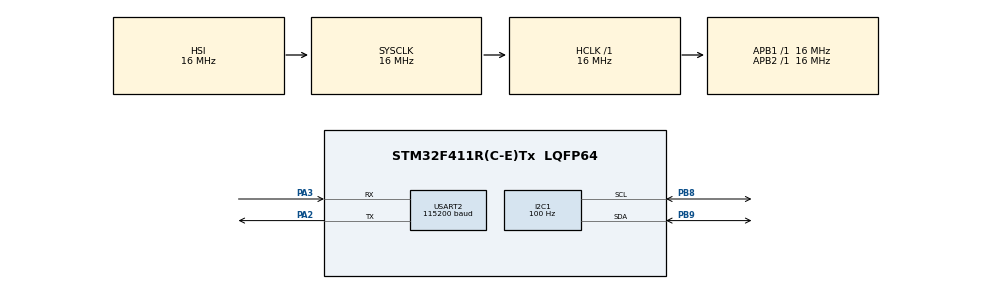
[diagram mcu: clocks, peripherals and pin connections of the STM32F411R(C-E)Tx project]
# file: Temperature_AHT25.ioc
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I2C1.ClockSpeed=100
Mcu.Family=STM32F4
Mcu.Name=STM32F411R(C-E)Tx
Mcu.Package=LQFP64
NVIC.PriorityGroup=NVIC_PRIORITYGROUP_4
PA2.Mode=Asynchronous
PA2.Signal=USART2_TX
PA3.Mode=Asynchronous
PA3.Signal=USART2_RX
PB8.Mode=I2C
PB8.Signal=I2C1_SCL
PB9.Mode=I2C
PB9.Signal=I2C1_SDA
ProjectManager.HeapSize=0x200
ProjectManager.StackSize=0x400
ProjectManager.TargetToolchain=STM32CubeIDE
RCC.AHBFreq_Value=16000000
RCC.APB1Freq_Value=16000000
RCC.APB2Freq_Value=16000000
RCC.CortexFreq_Value=16000000
RCC.HSE_VALUE=25000000
RCC.HSI_VALUE=16000000
RCC.LSE_VALUE=32768
RCC.SYSCLKFreq_VALUE=16000000
RCC.VCOOutputFreq_Value=192000000
USART2.BaudRate=115200
USART2.VirtualMode=VM_ASYNC
board=custom

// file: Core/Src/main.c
/* USER CODE BEGIN Header */
/**
  ******************************************************************************
  * @file           : main.c
  * @brief          : Main program body
  ******************************************************************************
  * @attention
  *
  * Copyright (c) 2023 STMicroelectronics.
  * All rights reserved.
  *
  * This software is licensed under terms that can be found in the LICENSE file
  * in the root directory of this software component.
  * If no LICENSE file comes with this software, it is provided AS-IS.
  *
  ******************************************************************************
  */
/* USER CODE END Header */
#include "main.h"
#include "stdio.h"
#include "string.h"

/* USER CODE BEGIN Includes */
#define AHT25_ADDR 0x38
#define AHT25_MEASURE_CMD 0xAC
#define REG_TEMP 0x00

/* USER CODE END Includes */

I2C_HandleTypeDef hi2c1;

UART_HandleTypeDef huart2;

/* USER CODE BEGIN PV */

//static const uint8_t AHT25_ADDR = 0x38 << 1;
//static const uint8_t REG_TEMP = 0xE1;
/* USER CODE END PV */

void SystemClock_Config(void);
static void MX_GPIO_Init(void);
static void MX_I2C1_Init(void);
static void MX_USART2_UART_Init(void);

int main(void)
{
  /* USER CODE BEGIN 1 */

//	HAL_StatusTypeDef ret;
//	uint8_t buf[12];
//	int16_t val;
//	float temp_c;

  /* USER CODE END 1 */
	  uint8_t buf[12];
	  int16_t temperature;
	  float temp_c;

  /* MCU Configuration--------------------------------------------------------*/

  /* Reset of all peripherals, Initializes the Flash interface and the Systick. */
  HAL_Init();

  /* Configure the system clock */
  SystemClock_Config();

  /* Initialize all configured peripherals */
  MX_GPIO_Init();
  MX_I2C1_Init();
  MX_USART2_UART_Init();

  /* Infinite loop */
  /* USER CODE BEGIN WHILE */
//  while (1)
//  {
//
//    // Tell TMP102 that we want to read from the temperature register
//    buf[0] = REG_TEMP;
//    ret = HAL_I2C_Master_Transmit(&hi2c1, AHT25_ADDR, buf, 1, HAL_MAX_DELAY);
//    HAL_Delay(500);
//    if ( ret != HAL_OK ) {
//      strcpy((char*)buf, "Error Tx\r\n");
//    } else {
//
//      // Read 2 bytes from the temperature register
//      ret = HAL_I2C_Master_Receive(&hi2c1, AHT25_ADDR, buf, 2, HAL_MAX_DELAY);
//      if ( ret != HAL_OK ) {
//        strcpy((char*)buf, "Error Rx\r\n");
//      } else {
//
//        //Combine the bytes
//        val = ((int16_t)buf[0] << 4) | (buf[1] >> 4);
//
//        // Convert to 2's complement, since temperature can be negative
//        if ( val > 0x7FF ) {
//          val |= 0xF000;
//        }
//
//        // Convert to float temperature value (Celsius)
//        temp_c = val * 0.0625;
//
//        // Convert temperature to decimal format
//        temp_c *= 100;
//        sprintf((char*)buf,
//              "%u.%u C\r\n",
//              ((unsigned int)temp_c / 100),
//              ((unsigned int)temp_c % 100));
//      }
//    }
//
//    // Send out buffer (temperature or error message)
//    HAL_UART_Transmit(&huart2, buf, strlen((char*)buf), HAL_MAX_DELAY);
//
//    // Wait
//    HAL_Delay(500);
//
//    /* USER CODE END WHILE */
//
//    /* USER CODE BEGIN 3 */
//  }
  /* USER CODE END 3 */
//  while (1)
//    {
//      buf[0] = ;
//      if (HAL_I2C_Master_Transmit(&hi2c1, AHT25_ADDR, buf, 1, 100) != HAL_OK)
//      {
//        strcpy((char*)buf, "Error Tx\r\n");
//
//        //strcpy((char*)buf, "Error Rx\r\n");
//      }
//      else
//      {
//        HAL_Delay(80);  // Wait for measurement completion (adjust delay if needed)
//
//        if (HAL_I2C_Master_Receive(&hi2c1, AHT25_ADDR, buf, 6, HAL_MAX_DELAY) != HAL_OK)
//        {
//          strcpy((char*)buf, "Error Rx\r\n");
//        }
//        else
//        {
//          temperature = ((int16_t)buf[2] << 8) | buf[3];
//
//          if (temperature > 0x7FF)
//          {
//            temperature = temperature | 0xF000;
//          }
//
//          temp_c = temperature * 0.1;
//
//          char temp_str[20];
//          sprintf(temp_str, "%.2f C\r\n", temp_c);
//          HAL_UART_Transmit(&huart2, (uint8_t*)temp_str, strlen(temp_str), HAL_MAX_DELAY);
//        }
//      }
//      HAL_UART_Transmit(&huart2, buf, strlen((char*)buf), HAL_MAX_DELAY);
//      HAL_Delay(500);
//    }

  while (1)
  {
    buf[0] = AHT25_MEASURE_CMD;

    if (HAL_I2C_Master_Transmit(&hi2c1, AHT25_ADDR, buf, 1, HAL_MAX_DELAY) != HAL_OK)
    {
      Error_Handler();
    }

    HAL_Delay(80);  // Wait for measurement completion (adjust delay if needed)

    if (HAL_I2C_Master_Receive(&hi2c1, AHT25_ADDR, buf, 6, HAL_MAX_DELAY) != HAL_OK)
    {
      Error_Handler();
    }

    temperature = ((int16_t)buf[2] << 8) | buf[3];

    if (temperature > 0x7FF)
    {
      temperature = temperature | 0xF000;
    }

    temp_c = temperature * 0.1;

    char temp_str[20];
    sprintf(temp_str, "%.2f C\r\n", temp_c);
    HAL_UART_Transmit(&huart2, (uint8_t*)temp_str, strlen(temp_str), HAL_MAX_DELAY);

    HAL_Delay(500);
  }

  /* USER CODE END 3 */
}

void SystemClock_Config(void)
{
  RCC_OscInitTypeDef RCC_OscInitStruct = {0};
  RCC_ClkInitTypeDef RCC_ClkInitStruct = {0};

  /** Configure the main internal regulator output voltage
  */
  __HAL_RCC_PWR_CLK_ENABLE();
  __HAL_PWR_VOLTAGESCALING_CONFIG(PWR_REGULATOR_VOLTAGE_SCALE1);

  /** Initializes the RCC Oscillators according to the specified parameters
  * in the RCC_OscInitTypeDef structure.
  */
  RCC_OscInitStruct.OscillatorType = RCC_OSCILLATORTYPE_HSI;
  RCC_OscInitStruct.HSIState = RCC_HSI_ON;
  RCC_OscInitStruct.HSICalibrationValue = RCC_HSICALIBRATION_DEFAULT;
  RCC_OscInitStruct.PLL.PLLState = RCC_PLL_NONE;
  if (HAL_RCC_OscConfig(&RCC_OscInitStruct) != HAL_OK)
  {
    Error_Handler();
  }

  /** Initializes the CPU, AHB and APB buses clocks
  */
  RCC_ClkInitStruct.ClockType = RCC_CLOCKTYPE_HCLK|RCC_CLOCKTYPE_SYSCLK
                              |RCC_CLOCKTYPE_PCLK1|RCC_CLOCKTYPE_PCLK2;
  RCC_ClkInitStruct.SYSCLKSource = RCC_SYSCLKSOURCE_HSI;
  RCC_ClkInitStruct.AHBCLKDivider = RCC_SYSCLK_DIV1;
  RCC_ClkInitStruct.APB1CLKDivider = RCC_HCLK_DIV1;
  RCC_ClkInitStruct.APB2CLKDivider = RCC_HCLK_DIV1;

  if (HAL_RCC_ClockConfig(&RCC_ClkInitStruct, FLASH_LATENCY_0) != HAL_OK)
  {
    Error_Handler();
  }
}

static void MX_I2C1_Init(void)
{

  hi2c1.Instance = I2C1;
  hi2c1.Init.ClockSpeed = 100;
  hi2c1.Init.DutyCycle = I2C_DUTYCYCLE_2;
  hi2c1.Init.OwnAddress1 = 0;
  hi2c1.Init.AddressingMode = I2C_ADDRESSINGMODE_7BIT;
  hi2c1.Init.DualAddressMode = I2C_DUALADDRESS_DISABLE;
  hi2c1.Init.OwnAddress2 = 0;
  hi2c1.Init.GeneralCallMode = I2C_GENERALCALL_DISABLE;
  hi2c1.Init.NoStretchMode = I2C_NOSTRETCH_DISABLE;
  if (HAL_I2C_Init(&hi2c1) != HAL_OK)
  {
    Error_Handler();
  }

}

static void MX_USART2_UART_Init(void)
{

  huart2.Instance = USART2;
  huart2.Init.BaudRate = 115200;
  huart2.Init.WordLength = UART_WORDLENGTH_8B;
  huart2.Init.StopBits = UART_STOPBITS_1;
  huart2.Init.Parity = UART_PARITY_NONE;
  huart2.Init.Mode = UART_MODE_TX_RX;
  huart2.Init.HwFlowCtl = UART_HWCONTROL_NONE;
  huart2.Init.OverSampling = UART_OVERSAMPLING_16;
  if (HAL_UART_Init(&huart2) != HAL_OK)
  {
    Error_Handler();
  }

}

static void MX_GPIO_Init(void)
{

  /* GPIO Ports Clock Enable */
  __HAL_RCC_GPIOA_CLK_ENABLE();
  __HAL_RCC_GPIOB_CLK_ENABLE();

}

void Error_Handler(void)
{
  __disable_irq();
  while (1)
  {
  }
}
